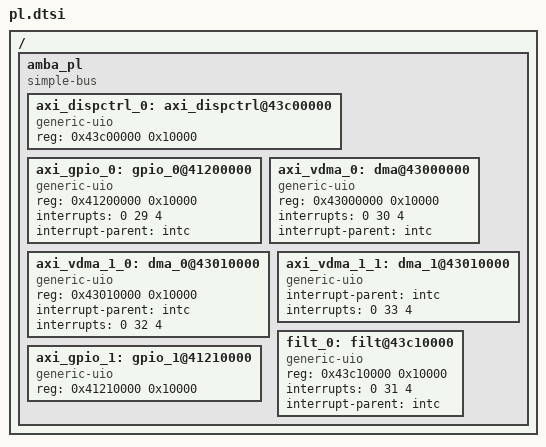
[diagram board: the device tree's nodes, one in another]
/*
 * CAUTION: This file is automatically generated by Xilinx.
 * Version: HSI 2016.2
 * Today is: Fri Aug 26 13:29:01 2016
*/


/ {
	amba_pl: amba_pl {
		#address-cells = <1>;
		#size-cells = <1>;
		compatible = "simple-bus";
		ranges ;
		axi_dispctrl_0: axi_dispctrl@43c00000 {
			compatible = "generic-uio";
			reg = <0x43c00000 0x10000>;
		};
		axi_gpio_0: gpio_0@41200000 {
			compatible = "generic-uio";
			reg = < 0x41200000 0x10000 >;
			interrupts = <0 29 4>;
			interrupt-parent = <&intc>;
		};
		axi_vdma_0: dma@43000000 {
			compatible = "generic-uio";
			reg = <0x43000000 0x10000>;
			interrupts = <0 30 4>;
			interrupt-parent = <&intc>;
		};
		axi_vdma_1_0: dma_0@43010000 {
			compatible = "generic-uio";			
			reg = <0x43010000 0x10000>;
			interrupt-parent = <&intc>;
			interrupts = <0 32 4>;
		};
		axi_vdma_1_1: dma_1@43010000 {
			compatible = "generic-uio";	
			interrupt-parent = <&intc>;
			interrupts = <0 33 4>;
		};
		filt_0: filt@43c10000 {
			compatible = "generic-uio";
			reg = <0x43c10000 0x10000>;			
			interrupts = <0 31 4>;
			interrupt-parent = <&intc>;
		};
		axi_gpio_1: gpio_1@41210000 {
			compatible = "generic-uio";
			reg = <0x41210000 0x10000>;
		};
	};
};
